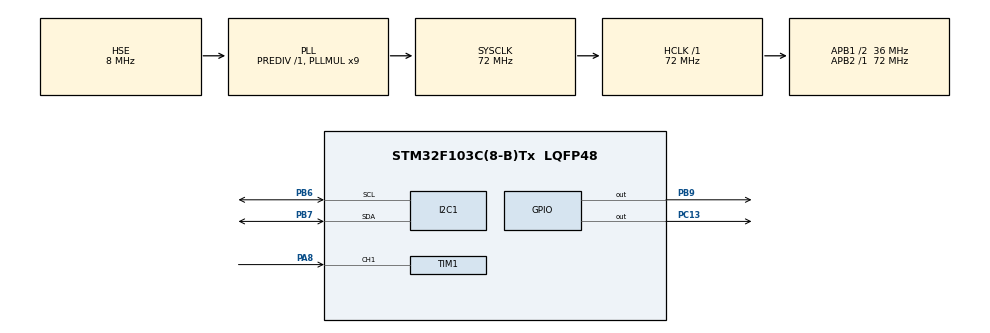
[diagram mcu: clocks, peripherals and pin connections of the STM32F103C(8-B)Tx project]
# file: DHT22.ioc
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Dma.Request0=TIM1_CH1
Dma.TIM1_CH1.0.Direction=DMA_PERIPH_TO_MEMORY
Dma.TIM1_CH1.0.Instance=DMA1_Channel2
Dma.TIM1_CH1.0.MemDataAlignment=DMA_MDATAALIGN_WORD
Dma.TIM1_CH1.0.MemInc=DMA_MINC_ENABLE
Dma.TIM1_CH1.0.Mode=DMA_CIRCULAR
Dma.TIM1_CH1.0.PeriphDataAlignment=DMA_PDATAALIGN_HALFWORD
Dma.TIM1_CH1.0.PeriphInc=DMA_PINC_DISABLE
Dma.TIM1_CH1.0.Priority=DMA_PRIORITY_VERY_HIGH
I2C1.I2C_Mode=I2C_Fast
Mcu.Family=STM32F1
Mcu.Name=STM32F103C(8-B)Tx
Mcu.Package=LQFP48
NVIC.DMA1_Channel2_IRQn=true\:0\:0\:false\:false\:true\:false\:true\:true
NVIC.FLASH_IRQn=true\:0\:0\:false\:false\:true\:true\:true\:true
NVIC.I2C1_ER_IRQn=true\:0\:0\:false\:false\:true\:true\:true\:true
NVIC.I2C1_EV_IRQn=true\:0\:0\:false\:false\:true\:true\:true\:true
NVIC.PVD_IRQn=true\:0\:0\:false\:false\:true\:true\:true\:true
NVIC.PriorityGroup=NVIC_PRIORITYGROUP_4
NVIC.RCC_IRQn=true\:0\:0\:false\:false\:true\:true\:false\:true
NVIC.TIM1_CC_IRQn=true\:0\:0\:false\:false\:true\:true\:true\:true
NVIC.TIM2_IRQn=true\:0\:0\:false\:false\:true\:true\:true\:true
PA13.Mode=Serial_Wire
PA13.Signal=SYS_JTMS-SWDIO
PA14.Mode=Serial_Wire
PA14.Signal=SYS_JTCK-SWCLK
PA8.Signal=S_TIM1_CH1
PB6.Mode=I2C
PB6.Signal=I2C1_SCL
PB7.Mode=I2C
PB7.Signal=I2C1_SDA
PB9.Signal=GPIO_Output
PC13-TAMPER-RTC.Signal=GPIO_Output
PD0-OSC_IN.Mode=HSE-External-Oscillator
PD0-OSC_IN.Signal=RCC_OSC_IN
PD1-OSC_OUT.Mode=HSE-External-Oscillator
PD1-OSC_OUT.Signal=RCC_OSC_OUT
ProjectManager.HeapSize=0x200
ProjectManager.StackSize=0x400
ProjectManager.TargetToolchain=STM32CubeIDE
RCC.AHBFreq_Value=72000000
RCC.APB1CLKDivider=RCC_HCLK_DIV2
RCC.APB1Freq_Value=36000000
RCC.APB1TimFreq_Value=72000000
RCC.APB2Freq_Value=72000000
RCC.APB2TimFreq_Value=72000000
RCC.HCLKFreq_Value=72000000
RCC.PLLMUL=RCC_PLL_MUL9
RCC.PLLSourceVirtual=RCC_PLLSOURCE_HSE
RCC.SYSCLKFreq_VALUE=72000000
RCC.SYSCLKSource=RCC_SYSCLKSOURCE_PLLCLK
RCC.USBFreq_Value=48000000
RCC.USBPrescaler=RCC_USBCLKSOURCE_PLL_DIV1_5
SH.S_TIM1_CH1.0=TIM1_CH1,Input_Capture1_from_TI1
TIM1.Channel-Input_Capture1_from_TI1=TIM_CHANNEL_1
TIM1.ICPolarity_CH1=TIM_INPUTCHANNELPOLARITY_FALLING
TIM1.Prescaler=71
TIM2.Period=9999
TIM2.Prescaler=7199
VP_TIM1_VS_ClockSourceINT.Mode=Internal
VP_TIM2_VS_ClockSourceINT.Mode=Internal
board=custom

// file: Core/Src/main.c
/* USER CODE BEGIN Header */
/**
  ******************************************************************************
  * @file           : main.c
  * @brief          : Main program body
  ******************************************************************************
  * @attention
  *
  * Copyright (c) 2025 STMicroelectronics.
  * All rights reserved.
  *
  * This software is licensed under terms that can be found in the LICENSE file
  * in the root directory of this software component.
  * If no LICENSE file comes with this software, it is provided AS-IS.
  *
  ******************************************************************************
  */
/* USER CODE END Header */
#include "main.h"

/* USER CODE BEGIN Includes */
#include "ssd1306.h"
/* USER CODE END Includes */

I2C_HandleTypeDef hi2c1;

TIM_HandleTypeDef htim1;
TIM_HandleTypeDef htim2;
DMA_HandleTypeDef hdma_tim1_ch1;

void SystemClock_Config(void);
static void MX_GPIO_Init(void);
static void MX_DMA_Init(void);
static void MX_I2C1_Init(void);
static void MX_TIM1_Init(void);
static void MX_TIM2_Init(void);

int main(void)
{

  /* MCU Configuration--------------------------------------------------------*/

  /* Reset of all peripherals, Initializes the Flash interface and the Systick. */
  HAL_Init();

  /* Configure the system clock */
  SystemClock_Config();

  /* Initialize all configured peripherals */
  MX_GPIO_Init();
  MX_DMA_Init();
  MX_I2C1_Init();
  MX_TIM1_Init();
  MX_TIM2_Init();
  /* USER CODE BEGIN 2 */

  HAL_TIM_Base_Start_IT(&htim1);
  HAL_TIM_Base_Start_IT(&htim2);
  HAL_Delay (100);

  /* USER CODE END 2 */

  /* Infinite loop */
  while (1)
  {

  }
}

void SystemClock_Config(void)
{
  RCC_OscInitTypeDef RCC_OscInitStruct = {0};
  RCC_ClkInitTypeDef RCC_ClkInitStruct = {0};

  /** Initializes the RCC Oscillators according to the specified parameters
  * in the RCC_OscInitTypeDef structure.
  */
  RCC_OscInitStruct.OscillatorType = RCC_OSCILLATORTYPE_HSE;
  RCC_OscInitStruct.HSEState = RCC_HSE_ON;
  RCC_OscInitStruct.HSEPredivValue = RCC_HSE_PREDIV_DIV1;
  RCC_OscInitStruct.HSIState = RCC_HSI_ON;
  RCC_OscInitStruct.PLL.PLLState = RCC_PLL_ON;
  RCC_OscInitStruct.PLL.PLLSource = RCC_PLLSOURCE_HSE;
  RCC_OscInitStruct.PLL.PLLMUL = RCC_PLL_MUL9;
  if (HAL_RCC_OscConfig(&RCC_OscInitStruct) != HAL_OK)
  {
    Error_Handler();
  }

  /** Initializes the CPU, AHB and APB buses clocks
  */
  RCC_ClkInitStruct.ClockType = RCC_CLOCKTYPE_HCLK|RCC_CLOCKTYPE_SYSCLK
                              |RCC_CLOCKTYPE_PCLK1|RCC_CLOCKTYPE_PCLK2;
  RCC_ClkInitStruct.SYSCLKSource = RCC_SYSCLKSOURCE_PLLCLK;
  RCC_ClkInitStruct.AHBCLKDivider = RCC_SYSCLK_DIV1;
  RCC_ClkInitStruct.APB1CLKDivider = RCC_HCLK_DIV2;
  RCC_ClkInitStruct.APB2CLKDivider = RCC_HCLK_DIV1;

  if (HAL_RCC_ClockConfig(&RCC_ClkInitStruct, FLASH_LATENCY_2) != HAL_OK)
  {
    Error_Handler();
  }
}

static void MX_I2C1_Init(void)
{

  hi2c1.Instance = I2C1;
  hi2c1.Init.ClockSpeed = 400000;
  hi2c1.Init.DutyCycle = I2C_DUTYCYCLE_2;
  hi2c1.Init.OwnAddress1 = 0;
  hi2c1.Init.AddressingMode = I2C_ADDRESSINGMODE_7BIT;
  hi2c1.Init.DualAddressMode = I2C_DUALADDRESS_DISABLE;
  hi2c1.Init.OwnAddress2 = 0;
  hi2c1.Init.GeneralCallMode = I2C_GENERALCALL_DISABLE;
  hi2c1.Init.NoStretchMode = I2C_NOSTRETCH_DISABLE;
  if (HAL_I2C_Init(&hi2c1) != HAL_OK)
  {
    Error_Handler();
  }

}

static void MX_TIM1_Init(void)
{

  /* USER CODE BEGIN TIM1_Init 0 */
	__HAL_RCC_TIM1_CLK_ENABLE();
  /* USER CODE END TIM1_Init 0 */

  TIM_ClockConfigTypeDef sClockSourceConfig = {0};
  TIM_MasterConfigTypeDef sMasterConfig = {0};
  TIM_IC_InitTypeDef sConfigIC = {0};

  htim1.Instance = TIM1;
  htim1.Init.Prescaler = 71;
  htim1.Init.CounterMode = TIM_COUNTERMODE_UP;
  htim1.Init.Period = 65535;
  htim1.Init.ClockDivision = TIM_CLOCKDIVISION_DIV1;
  htim1.Init.RepetitionCounter = 0;
  htim1.Init.AutoReloadPreload = TIM_AUTORELOAD_PRELOAD_DISABLE;
  if (HAL_TIM_Base_Init(&htim1) != HAL_OK)
  {
    Error_Handler();
  }
  sClockSourceConfig.ClockSource = TIM_CLOCKSOURCE_INTERNAL;
  if (HAL_TIM_ConfigClockSource(&htim1, &sClockSourceConfig) != HAL_OK)
  {
    Error_Handler();
  }
  if (HAL_TIM_IC_Init(&htim1) != HAL_OK)
  {
    Error_Handler();
  }
  sMasterConfig.MasterOutputTrigger = TIM_TRGO_RESET;
  sMasterConfig.MasterSlaveMode = TIM_MASTERSLAVEMODE_DISABLE;
  if (HAL_TIMEx_MasterConfigSynchronization(&htim1, &sMasterConfig) != HAL_OK)
  {
    Error_Handler();
  }
  sConfigIC.ICPolarity = TIM_INPUTCHANNELPOLARITY_FALLING;
  sConfigIC.ICSelection = TIM_ICSELECTION_DIRECTTI;
  sConfigIC.ICPrescaler = TIM_ICPSC_DIV1;
  sConfigIC.ICFilter = 0;
  if (HAL_TIM_IC_ConfigChannel(&htim1, &sConfigIC, TIM_CHANNEL_1) != HAL_OK)
  {
    Error_Handler();
  }
  /* USER CODE BEGIN TIM1_Init 2 */
  __HAL_LINKDMA(&htim1, hdma[TIM_DMA_ID_CC1], hdma_tim1_ch1);
  /* USER CODE END TIM1_Init 2 */

}

static void MX_TIM2_Init(void)
{

  TIM_ClockConfigTypeDef sClockSourceConfig = {0};
  TIM_MasterConfigTypeDef sMasterConfig = {0};

  htim2.Instance = TIM2;
  htim2.Init.Prescaler = 7199;
  htim2.Init.CounterMode = TIM_COUNTERMODE_UP;
  htim2.Init.Period = 9999;
  htim2.Init.ClockDivision = TIM_CLOCKDIVISION_DIV1;
  htim2.Init.AutoReloadPreload = TIM_AUTORELOAD_PRELOAD_DISABLE;
  if (HAL_TIM_Base_Init(&htim2) != HAL_OK)
  {
    Error_Handler();
  }
  sClockSourceConfig.ClockSource = TIM_CLOCKSOURCE_INTERNAL;
  if (HAL_TIM_ConfigClockSource(&htim2, &sClockSourceConfig) != HAL_OK)
  {
    Error_Handler();
  }
  sMasterConfig.MasterOutputTrigger = TIM_TRGO_RESET;
  sMasterConfig.MasterSlaveMode = TIM_MASTERSLAVEMODE_DISABLE;
  if (HAL_TIMEx_MasterConfigSynchronization(&htim2, &sMasterConfig) != HAL_OK)
  {
    Error_Handler();
  }

}

static void MX_DMA_Init(void)
{

  /* DMA controller clock enable */
  __HAL_RCC_DMA1_CLK_ENABLE();

  /* DMA interrupt init */
  /* DMA1_Channel2_IRQn interrupt configuration */
  HAL_NVIC_SetPriority(DMA1_Channel2_IRQn, 0, 0);
  HAL_NVIC_EnableIRQ(DMA1_Channel2_IRQn);

}

static void MX_GPIO_Init(void)
{
  GPIO_InitTypeDef GPIO_InitStruct = {0};

  /* GPIO Ports Clock Enable */
  __HAL_RCC_GPIOC_CLK_ENABLE();
  __HAL_RCC_GPIOD_CLK_ENABLE();
  __HAL_RCC_GPIOA_CLK_ENABLE();
  __HAL_RCC_GPIOB_CLK_ENABLE();

  /*Configure GPIO pin Output Level */
  HAL_GPIO_WritePin(GPIOC, GPIO_PIN_13, GPIO_PIN_RESET);

  /*Configure GPIO pin Output Level */
  HAL_GPIO_WritePin(GPIOB, GPIO_PIN_9, GPIO_PIN_RESET);

  /*Configure GPIO pin : PC13 */
  GPIO_InitStruct.Pin = GPIO_PIN_13;
  GPIO_InitStruct.Mode = GPIO_MODE_OUTPUT_PP;
  GPIO_InitStruct.Pull = GPIO_NOPULL;
  GPIO_InitStruct.Speed = GPIO_SPEED_FREQ_LOW;
  HAL_GPIO_Init(GPIOC, &GPIO_InitStruct);

  /*Configure GPIO pin : PB9 */
  GPIO_InitStruct.Pin = GPIO_PIN_9;
  GPIO_InitStruct.Mode = GPIO_MODE_OUTPUT_PP;
  GPIO_InitStruct.Pull = GPIO_NOPULL;
  GPIO_InitStruct.Speed = GPIO_SPEED_FREQ_LOW;
  HAL_GPIO_Init(GPIOB, &GPIO_InitStruct);

}

/* USER CODE BEGIN 4 */
/*int _write(int file, char *ptr, int len) {
    //CDC_Transmit_FS((uint8_t*) ptr, len); return len;
}*/
/* USER CODE END 4 */

void Error_Handler(void)
{
  __disable_irq();
  while (1)
  {
  }
}
